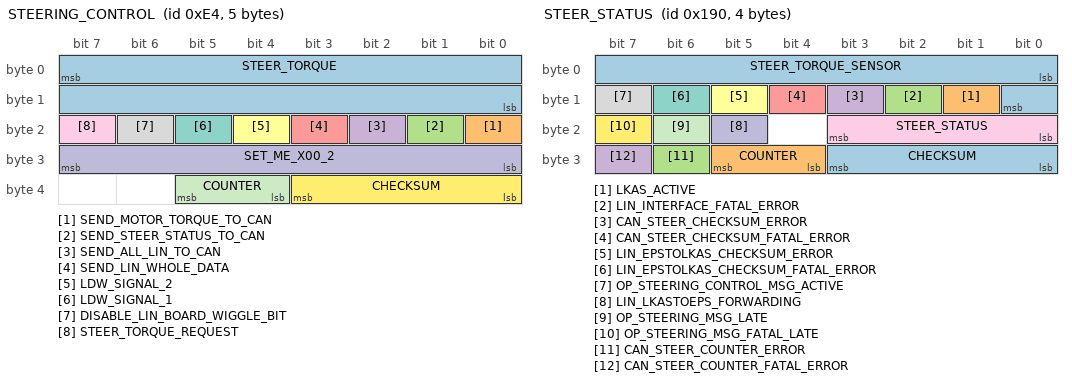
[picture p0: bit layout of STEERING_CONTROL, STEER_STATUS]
BO_ 228 STEERING_CONTROL: 5 ADAS
 SG_ STEER_TORQUE : 7|16@0- (1,0) [-3840|3840] "" EPS
 SG_ SEND_MOTOR_TORQUE_TO_CAN : 16|1@0+ (1,0) [0|1] "" XXX
 SG_ SEND_STEER_STATUS_TO_CAN : 17|1@0+ (1,0) [0|1] "" XXX
 SG_ SEND_ALL_LIN_TO_CAN : 18|1@0+ (1,0) [0|1] "" XXX
 SG_ SEND_LIN_WHOLE_DATA : 19|1@0+ (1,0) [0|1] "" XXX
 SG_ LDW_SIGNAL_2 : 20|1@0+ (1,0) [0|1] "" XXX
 SG_ LDW_SIGNAL_1 : 21|1@0+ (1,0) [0|1] "" XXX
 SG_ DISABLE_LIN_BOARD_WIGGLE_BIT : 22|1@0+ (1,0) [0|1] "" XXX
 SG_ STEER_TORQUE_REQUEST : 23|1@0+ (1,0) [0|1] "" EPS
 SG_ SET_ME_X00_2 : 31|8@0+ (1,0) [0|0] "" EPS
 SG_ COUNTER : 37|2@0+ (1,0) [0|3] "" EPS
 SG_ CHECKSUM : 35|4@0+ (1,0) [0|15] "" EPS

BO_ 400 STEER_STATUS: 4 EPS
 SG_ STEER_TORQUE_SENSOR : 0|9@1- (1,0) [-256|256] "" XXX
 SG_ LKAS_ACTIVE : 9|1@0+ (1,0) [0|1] "" XXX
 SG_ LIN_INTERFACE_FATAL_ERROR : 10|1@0+ (1,0) [0|1] "" XXX
 SG_ CAN_STEER_CHECKSUM_ERROR : 11|1@0+ (1,0) [0|1] "" XXX
 SG_ CAN_STEER_CHECKSUM_FATAL_ERROR : 12|1@0+ (1,0) [0|1] "" XXX
 SG_ LIN_EPSTOLKAS_CHECKSUM_ERROR : 13|1@0+ (1,0) [0|1] "" XXX
 SG_ LIN_EPSTOLKAS_CHECKSUM_FATAL_ERROR : 14|1@0+ (1,0) [0|1] "" XXX
 SG_ OP_STEERING_CONTROL_MSG_ACTIVE : 15|1@0+ (1,0) [0|1] "" XXX
 SG_ STEER_STATUS : 16|4@1+ (1,0) [0|15] "" XXX
 SG_ LIN_LKASTOEPS_FORWARDING : 21|1@0+ (1,0) [0|1] "" XXX
 SG_ OP_STEERING_MSG_LATE : 22|1@0+ (1,0) [0|1] "" XXX
 SG_ OP_STEERING_MSG_FATAL_LATE : 23|1@0+ (1,0) [0|1] "" XXX
 SG_ CHECKSUM : 27|4@0+ (1,0) [0|15] "" EON
 SG_ COUNTER : 29|2@0+ (1,0) [0|3] "" EON
 SG_ CAN_STEER_COUNTER_ERROR : 30|1@0+ (1,0) [0|1] "" XXX
 SG_ CAN_STEER_COUNTER_FATAL_ERROR : 31|1@0+ (1,0) [0|1] "" XXX

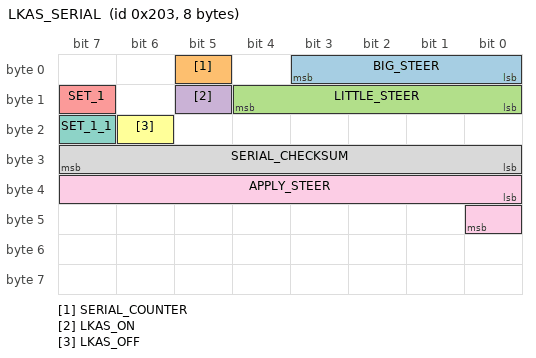
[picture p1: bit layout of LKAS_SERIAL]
BO_ 515 LKAS_SERIAL: 8 XXX
 SG_ BIG_STEER : 3|4@0- (1,0) [0|15] "" XXX
 SG_ SERIAL_COUNTER : 5|1@0+ (1,0) [0|1] "" XXX
 SG_ LITTLE_STEER : 12|5@0- (1,0) [0|31] "" XXX
 SG_ LKAS_ON : 13|1@0+ (1,0) [0|1] "" XXX
 SG_ SET_1 : 15|1@0+ (1,0) [0|1] "" XXX
 SG_ LKAS_OFF : 22|1@0+ (1,0) [0|1] "" XXX
 SG_ SET_1_1 : 23|1@0+ (1,0) [0|1] "" XXX
 SG_ SERIAL_CHECKSUM : 24|8@1+ (1,32) [0|255] "" XXX
 SG_ APPLY_STEER : 32|9@1- (1,0) [-256|255] "" XXX

BO_ 521 LIN_DATA_IN: 8 XXX
 SG_ BIG_STEER : 0|4@1+ (1,0) [0|15] "" XXX
 SG_ UNK_SIGNAL : 4|1@0+ (1,0) [0|1] "" XXX
 SG_ LITTLE_STEER : 12|5@0+ (1,0) [0|31] "" XXX
 SG_ LKAS_ENABLED : 13|1@0+ (1,0) [0|1] "" XXX
 SG_ UNK_LDW_SIGNAL2 : 20|1@0+ (1,0) [0|1] "" XXX
 SG_ UNK_LDW_SIGNAL1 : 21|1@0+ (1,0) [0|1] "" XXX
 SG_ LKAS_ENABLED_INVERT : 22|1@0+ (1,0) [0|1] "" XXX
 SG_ BIG_DRIVER_TORQUE : 24|4@1+ (1,0) [0|15] "" XXX
 SG_ LIN_EPS_B0_O4 : 28|1@0+ (1,0) [0|1] "" XXX
 SG_ EPS_TO_LKAS_COUNTER_BIT : 29|1@0+ (1,0) [0|1] "" XXX
 SG_ SMALL_DRIVER_TORQUE : 36|5@0+ (1,0) [0|31] "" XXX
 SG_ LKAS_ON_FROM_EPS : 37|1@0+ (1,0) [0|1] "" XXX
 SG_ LIN_EPS_B1_O6 : 38|1@0+ (1,0) [0|1] "" XXX
 SG_ LIN_EPS_B2_O0_2 : 40|3@1+ (1,0) [0|7] "" XXX
 SG_ BIG_MOTOR_TORQUE : 45|3@0- (1,0) [0|7] "" XXX
 SG_ LKAS_ON_FROM_EPS_INVERT : 46|1@0+ (1,0) [0|1] "" XXX
 SG_ SMALL_MOTOR_TORQUE : 54|7@0+ (1,0) [0|127] "" XXX
 SG_ CAN_CHECKSUM : 56|4@1+ (1,0) [0|15] "" XXX
 SG_ CAN_COUNTER : 61|2@0+ (1,0) [0|3] "" XXX

CM_ "Serial Steering V2 (SSV2) board, 2016-17 Accord. Layout from mlocoteta/opendbc a9b333c (identical to 0.9_SSV2 c6d929e).";
CM_ "The board sits on the camera side (panda bus 2): it reads STEERING_CONTROL there and replaces the camera's LKAS serial frame to the EPS.";
CM_ SG_ 228 SEND_MOTOR_TORQUE_TO_CAN "SSV2 board config bit; openpilot leaves it 0";
CM_ SG_ 228 SEND_STEER_STATUS_TO_CAN "SSV2 board config bit; openpilot leaves it 0";
CM_ SG_ 228 SEND_ALL_LIN_TO_CAN "SSV2 board config bit; openpilot leaves it 0";
CM_ SG_ 228 SEND_LIN_WHOLE_DATA "SSV2 board config bit; openpilot leaves it 0";
CM_ SG_ 228 DISABLE_LIN_BOARD_WIGGLE_BIT "board toggles the LSB of the applied torque when 0; openpilot leaves it 0";
CM_ SG_ 400 OP_STEERING_CONTROL_MSG_ACTIVE "set while the board sees STEERING_CONTROL";
CM_ SG_ 400 STEER_STATUS "EPS status passed through by the board; 11 is EPS fail for oversteer";
CM_ SG_ 515 APPLY_STEER "big_steer and little_steer put together";
CM_ SG_ 521 UNK_SIGNAL "never seen this move";

VAL_ 400 STEER_STATUS 6 "tmp_fault" 5 "fault_1" 4 "no_torque_alert_2" 3 "low_speed_lockout" 2 "no_torque_alert_1" 0 "normal" ;
